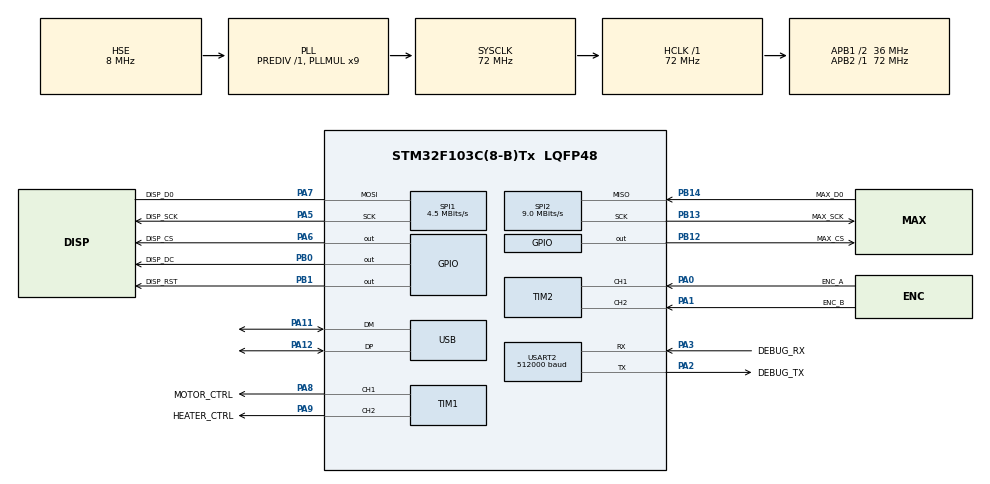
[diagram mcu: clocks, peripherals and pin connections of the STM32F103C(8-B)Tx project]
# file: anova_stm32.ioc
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Dma.Request0=USART2_RX
Dma.USART2_RX.0.Direction=DMA_PERIPH_TO_MEMORY
Dma.USART2_RX.0.Instance=DMA1_Channel6
Dma.USART2_RX.0.MemDataAlignment=DMA_MDATAALIGN_BYTE
Dma.USART2_RX.0.MemInc=DMA_MINC_ENABLE
Dma.USART2_RX.0.Mode=DMA_NORMAL
Dma.USART2_RX.0.PeriphDataAlignment=DMA_PDATAALIGN_BYTE
Dma.USART2_RX.0.PeriphInc=DMA_PINC_DISABLE
Dma.USART2_RX.0.Priority=DMA_PRIORITY_LOW
FREERTOS.Tasks01=defaultTask,0,128,StartDefaultTask,Default,NULL
FREERTOS.configTOTAL_HEAP_SIZE=8192
Mcu.Family=STM32F1
Mcu.Name=STM32F103C(8-B)Tx
Mcu.Package=LQFP48
NVIC.DMA1_Channel6_IRQn=true\:5\:0\:false\:false\:true\:true\:false
NVIC.PriorityGroup=NVIC_PRIORITYGROUP_4
NVIC.USART2_IRQn=true\:5\:0\:false\:false\:true\:true\:true
NVIC.USB_LP_CAN1_RX0_IRQn=true\:5\:0\:false\:false\:true\:true\:false
PA0-WKUP.GPIO_Label=ENC_A
PA0-WKUP.Signal=S_TIM2_CH1_ETR
PA1.GPIO_Label=ENC_B
PA1.Signal=S_TIM2_CH2
PA11.Mode=Device
PA11.Signal=USB_DM
PA12.Mode=Device
PA12.Signal=USB_DP
PA13.GPIO_Label=SWDIO
PA13.Mode=Trace_Asynchronous_SW
PA13.Signal=SYS_JTMS-SWDIO
PA14.GPIO_Label=SWCLK
PA14.Mode=Trace_Asynchronous_SW
PA14.Signal=SYS_JTCK-SWCLK
PA2.GPIO_Label=DEBUG_TX
PA2.Mode=Asynchronous
PA2.Signal=USART2_TX
PA3.GPIO_Label=DEBUG_RX
PA3.Mode=Asynchronous
PA3.Signal=USART2_RX
PA5.GPIO_Label=DISP_SCK
PA5.Mode=Simplex_Bidirectional_Master
PA5.Signal=SPI1_SCK
PA6.GPIO_Label=DISP_CS
PA6.Signal=GPIO_Output
PA7.GPIO_Label=DISP_D0
PA7.Mode=Simplex_Bidirectional_Master
PA7.Signal=SPI1_MOSI
PA8.GPIO_Label=MOTOR_CTRL
PA8.Signal=S_TIM1_CH1
PA9.GPIO_Label=HEATER_CTRL
PA9.Signal=S_TIM1_CH2
PB0.GPIO_Label=DISP_DC
PB0.Signal=GPIO_Output
PB1.GPIO_Label=DISP_RST
PB1.Signal=GPIO_Output
PB12.GPIO_Label=MAX_CS
PB12.Signal=GPIO_Output
PB13.GPIO_Label=MAX_SCK
PB13.Mode=RX_Only_Simplex_Unidirect_Master
PB13.Signal=SPI2_SCK
PB14.GPIO_Label=MAX_D0
PB14.Mode=RX_Only_Simplex_Unidirect_Master
PB14.Signal=SPI2_MISO
PB3.GPIO_Label=SWO
PB3.Mode=Trace_Asynchronous_SW
PB3.Signal=SYS_JTDO-TRACESWO
PD0-OSC_IN.Mode=HSE-External-Oscillator
PD0-OSC_IN.Signal=RCC_OSC_IN
PD1-OSC_OUT.Mode=HSE-External-Oscillator
PD1-OSC_OUT.Signal=RCC_OSC_OUT
ProjectManager.HeapSize=0x200
ProjectManager.StackSize=0x400
ProjectManager.TargetToolchain=Makefile
RCC.AHBFreq_Value=72000000
RCC.APB1CLKDivider=RCC_HCLK_DIV2
RCC.APB1Freq_Value=36000000
RCC.APB1TimFreq_Value=72000000
RCC.APB2Freq_Value=72000000
RCC.APB2TimFreq_Value=72000000
RCC.HCLKFreq_Value=72000000
RCC.PLLMUL=RCC_PLL_MUL9
RCC.SYSCLKFreq_VALUE=72000000
RCC.SYSCLKSource=RCC_SYSCLKSOURCE_PLLCLK
RCC.USBFreq_Value=48000000
RCC.USBPrescaler=RCC_USBCLKSOURCE_PLL_DIV1_5
SH.S_TIM1_CH1.0=TIM1_CH1,PWM Generation1 CH1
SH.S_TIM1_CH2.0=TIM1_CH2,PWM Generation2 CH2
SH.S_TIM2_CH1_ETR.0=TIM2_CH1,Encoder_Interface
SH.S_TIM2_CH2.0=TIM2_CH2,Encoder_Interface
SPI1.BaudRatePrescaler=SPI_BAUDRATEPRESCALER_16
SPI1.CalculateBaudRate=4.5 MBits/s
SPI1.Direction=SPI_DIRECTION_1LINE
SPI1.Mode=SPI_MODE_MASTER
SPI1.VirtualType=VM_MASTER
SPI2.BaudRatePrescaler=SPI_BAUDRATEPRESCALER_4
SPI2.CalculateBaudRate=9.0 MBits/s
SPI2.Direction=SPI_DIRECTION_2LINES_RXONLY
SPI2.Mode=SPI_MODE_MASTER
SPI2.VirtualType=VM_MASTER
TIM1.Channel-PWM\ Generation1\ CH1=TIM_CHANNEL_1
TIM1.Channel-PWM\ Generation2\ CH2=TIM_CHANNEL_2
TIM2.EncoderMode=TIM_ENCODERMODE_TI12
USART2.BaudRate=512000
USART2.VirtualMode=VM_ASYNC
USB.ep0_mps=DEP0CTL_MPS_64
USB_DEVICE.CLASS_NAME_FS=CDC
USB_DEVICE.VirtualMode=Cdc
USB_DEVICE.VirtualModeFS=Cdc_FS
VP_FREERTOS_VS_ENABLE.Mode=Enabled
VP_USB_DEVICE_VS_USB_DEVICE_CDC_FS.Mode=CDC_FS
board=anova_stm32

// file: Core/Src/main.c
/**
  ******************************************************************************
  * @file           : main.c
  * @brief          : Main program body
  ******************************************************************************
  * This notice applies to any and all portions of this file
  * that are not between comment pairs USER CODE BEGIN and
  * USER CODE END. Other portions of this file, whether
  * inserted by the user or by software development tools
  * are owned by their respective copyright owners.
  *
  * Copyright (c) 2018 STMicroelectronics International N.V.
  * All rights reserved.
  *
  * Redistribution and use in source and binary forms, with or without
  * modification, are permitted, provided that the following conditions are met:
  *
  * 1. Redistribution of source code must retain the above copyright notice,
  *    this list of conditions and the following disclaimer.
  * 2. Redistributions in binary form must reproduce the above copyright notice,
  *    this list of conditions and the following disclaimer in the documentation
  *    and/or other materials provided with the distribution.
  * 3. Neither the name of STMicroelectronics nor the names of other
  *    contributors to this software may be used to endorse or promote products
  *    derived from this software without specific written permission.
  * 4. This software, including modifications and/or derivative works of this
  *    software, must execute solely and exclusively on microcontroller or
  *    microprocessor devices manufactured by or for STMicroelectronics.
  * 5. Redistribution and use of this software other than as permitted under
  *    this license is void and will automatically terminate your rights under
  *    this license.
  *
  * THIS SOFTWARE IS PROVIDED BY STMICROELECTRONICS AND CONTRIBUTORS "AS IS"
  * AND ANY EXPRESS, IMPLIED OR STATUTORY WARRANTIES, INCLUDING, BUT NOT
  * LIMITED TO, THE IMPLIED WARRANTIES OF MERCHANTABILITY, FITNESS FOR A
  * PARTICULAR PURPOSE AND NON-INFRINGEMENT OF THIRD PARTY INTELLECTUAL PROPERTY
  * RIGHTS ARE DISCLAIMED TO THE FULLEST EXTENT PERMITTED BY LAW. IN NO EVENT
  * SHALL STMICROELECTRONICS OR CONTRIBUTORS BE LIABLE FOR ANY DIRECT, INDIRECT,
  * INCIDENTAL, SPECIAL, EXEMPLARY, OR CONSEQUENTIAL DAMAGES (INCLUDING, BUT NOT
  * LIMITED TO, PROCUREMENT OF SUBSTITUTE GOODS OR SERVICES; LOSS OF USE, DATA,
  * OR PROFITS; OR BUSINESS INTERRUPTION) HOWEVER CAUSED AND ON ANY THEORY OF
  * LIABILITY, WHETHER IN CONTRACT, STRICT LIABILITY, OR TORT (INCLUDING
  * NEGLIGENCE OR OTHERWISE) ARISING IN ANY WAY OUT OF THE USE OF THIS SOFTWARE,
  * EVEN IF ADVISED OF THE POSSIBILITY OF SUCH DAMAGE.
  *
  ******************************************************************************
  */
#include "main.h"
#include "stm32f1xx_hal.h"
#include "cmsis_os.h"
#include "dma.h"
#include "spi.h"
#include "tim.h"
#include "usart.h"
#include "usb_device.h"
#include "gpio.h"

/* USER CODE BEGIN Includes */
#include "application.h"
/* USER CODE END Includes */

/* USER CODE BEGIN PV */
/* Private variables ---------------------------------------------------------*/

/* USER CODE END PV */

void SystemClock_Config(void);
void MX_FREERTOS_Init(void);

/* USER CODE BEGIN PFP */
/* Private function prototypes -----------------------------------------------*/

/* USER CODE END PFP */

int main(void)
{

  /* MCU Configuration----------------------------------------------------------*/

  /* Reset of all peripherals, Initializes the Flash interface and the Systick. */
  HAL_Init();

  /* Configure the system clock */
  SystemClock_Config();

  /* Initialize all configured peripherals */
  MX_GPIO_Init();
  MX_DMA_Init();
  MX_SPI1_Init();
  MX_SPI2_Init();
  MX_USART2_UART_Init();
  MX_TIM1_Init();
  MX_TIM2_Init();
  /* USER CODE BEGIN 2 */
    app_main();
  /* USER CODE END 2 */

  /* Call init function for freertos objects (in freertos.c) */
  MX_FREERTOS_Init();

  /* Start scheduler */
  osKernelStart();

  /* We should never get here as control is now taken by the scheduler */

  /* Infinite loop */
  while (1)
  {

  }

}

void SystemClock_Config(void)
{

  RCC_OscInitTypeDef RCC_OscInitStruct;
  RCC_ClkInitTypeDef RCC_ClkInitStruct;
  RCC_PeriphCLKInitTypeDef PeriphClkInit;

    /**Initializes the CPU, AHB and APB busses clocks
    */
  RCC_OscInitStruct.OscillatorType = RCC_OSCILLATORTYPE_HSE;
  RCC_OscInitStruct.HSEState = RCC_HSE_ON;
  RCC_OscInitStruct.HSEPredivValue = RCC_HSE_PREDIV_DIV1;
  RCC_OscInitStruct.HSIState = RCC_HSI_ON;
  RCC_OscInitStruct.PLL.PLLState = RCC_PLL_ON;
  RCC_OscInitStruct.PLL.PLLSource = RCC_PLLSOURCE_HSE;
  RCC_OscInitStruct.PLL.PLLMUL = RCC_PLL_MUL9;
  if (HAL_RCC_OscConfig(&RCC_OscInitStruct) != HAL_OK)
  {
    _Error_Handler(__FILE__, __LINE__);
  }

    /**Initializes the CPU, AHB and APB busses clocks
    */
  RCC_ClkInitStruct.ClockType = RCC_CLOCKTYPE_HCLK|RCC_CLOCKTYPE_SYSCLK
                              |RCC_CLOCKTYPE_PCLK1|RCC_CLOCKTYPE_PCLK2;
  RCC_ClkInitStruct.SYSCLKSource = RCC_SYSCLKSOURCE_PLLCLK;
  RCC_ClkInitStruct.AHBCLKDivider = RCC_SYSCLK_DIV1;
  RCC_ClkInitStruct.APB1CLKDivider = RCC_HCLK_DIV2;
  RCC_ClkInitStruct.APB2CLKDivider = RCC_HCLK_DIV1;

  if (HAL_RCC_ClockConfig(&RCC_ClkInitStruct, FLASH_LATENCY_2) != HAL_OK)
  {
    _Error_Handler(__FILE__, __LINE__);
  }

  PeriphClkInit.PeriphClockSelection = RCC_PERIPHCLK_USB;
  PeriphClkInit.UsbClockSelection = RCC_USBCLKSOURCE_PLL_DIV1_5;
  if (HAL_RCCEx_PeriphCLKConfig(&PeriphClkInit) != HAL_OK)
  {
    _Error_Handler(__FILE__, __LINE__);
  }

    /**Configure the Systick interrupt time
    */
  HAL_SYSTICK_Config(HAL_RCC_GetHCLKFreq()/1000);

    /**Configure the Systick
    */
  HAL_SYSTICK_CLKSourceConfig(SYSTICK_CLKSOURCE_HCLK);

  /* SysTick_IRQn interrupt configuration */
  HAL_NVIC_SetPriority(SysTick_IRQn, 15, 0);
}

void _Error_Handler(char *file, int line)
{
  while(1)
  {
  }
}

/************************ (C) COPYRIGHT STMicroelectronics *****END OF FILE****/
